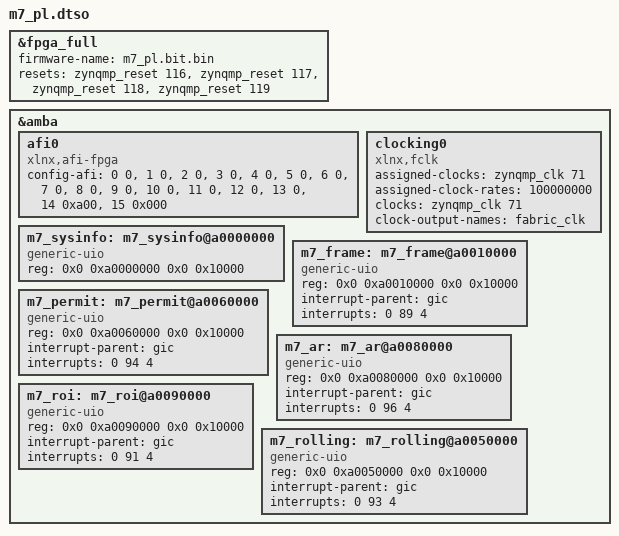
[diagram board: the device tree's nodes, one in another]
// GENERATED by tools/m7pl_gen.py overlay from bd/m7_bd.tcl -- do not edit.
// Device-tree overlay for `xmutil loadapp` / dfx-mgr on KV260 (XRT_FLAT shell).
// fpga_full/afi0/clocking0 follow the layout of the Kria base-platform
// overlays (checked against a decompiled U19 KV260 pl.dtbo, a third-party
// package; the values here are ours). afi0: HP ports and HPM0/1_FPD 128-bit,
// matching the PS port widths in bd/m7_bd.tcl. clocking0 = pl_clk0.
// Blocks bind to generic-uio only when the kernel command line has
// uio_pdrv_genirq.of_id=generic-uio; the test program also works through
// /dev/mem without UIO.
/dts-v1/;
/plugin/;

&fpga_full {
	#address-cells = <2>;
	#size-cells = <2>;
	firmware-name = "m7_pl.bit.bin";
	resets = <&zynqmp_reset 116>, <&zynqmp_reset 117>, <&zynqmp_reset 118>, <&zynqmp_reset 119>;
};

&amba {
	#address-cells = <2>;
	#size-cells = <2>;
	afi0: afi0 {
		compatible = "xlnx,afi-fpga";
		config-afi = <0 0>, <1 0>, <2 0>, <3 0>, <4 0>, <5 0>, <6 0>, <7 0>, <8 0>, <9 0>, <10 0>, <11 0>, <12 0>, <13 0>, <14 0xa00>, <15 0x000>;
	};
	clocking0: clocking0 {
		compatible = "xlnx,fclk";
		#clock-cells = <0>;
		assigned-clocks = <&zynqmp_clk 71>;
		assigned-clock-rates = <100000000>;
		clocks = <&zynqmp_clk 71>;
		clock-output-names = "fabric_clk";
	};
	m7_sysinfo: m7_sysinfo@a0000000 {
		compatible = "generic-uio";
		reg = <0x0 0xa0000000 0x0 0x10000>;
	};
	m7_frame: m7_frame@a0010000 {
		compatible = "generic-uio";
		reg = <0x0 0xa0010000 0x0 0x10000>;
		interrupt-parent = <&gic>;
		interrupts = <0 89 4>;
	};
	m7_permit: m7_permit@a0060000 {
		compatible = "generic-uio";
		reg = <0x0 0xa0060000 0x0 0x10000>;
		interrupt-parent = <&gic>;
		interrupts = <0 94 4>;
	};
	m7_ar: m7_ar@a0080000 {
		compatible = "generic-uio";
		reg = <0x0 0xa0080000 0x0 0x10000>;
		interrupt-parent = <&gic>;
		interrupts = <0 96 4>;
	};
	m7_roi: m7_roi@a0090000 {
		compatible = "generic-uio";
		reg = <0x0 0xa0090000 0x0 0x10000>;
		interrupt-parent = <&gic>;
		interrupts = <0 91 4>;
	};
	m7_rolling: m7_rolling@a0050000 {
		compatible = "generic-uio";
		reg = <0x0 0xa0050000 0x0 0x10000>;
		interrupt-parent = <&gic>;
		interrupts = <0 93 4>;
	};
};
